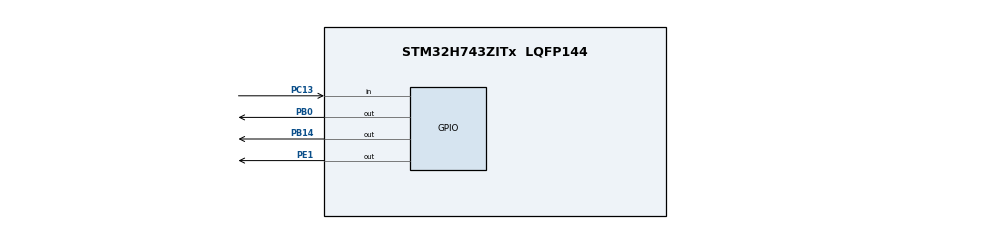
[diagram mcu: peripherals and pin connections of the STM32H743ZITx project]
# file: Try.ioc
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CORTEX_M7.default_mode_Activation=1
Mcu.Family=STM32H7
Mcu.Name=STM32H743ZITx
Mcu.Package=LQFP144
NUCLEO-H743ZI2.BUTTON=1
NUCLEO-H743ZI2.LD1=true
NUCLEO-H743ZI2.LD2=true
NUCLEO-H743ZI2.LD3=true
NUCLEO-H743ZI2.VCP=true
NVIC.EXTI15_10_IRQn=true\:0\:0\:false\:false\:true\:false\:true\:true
NVIC.PriorityGroup=NVIC_PRIORITYGROUP_4
PA13\ (JTMS/SWDIO).GPIO_Label=JTMS
PA13\ (JTMS/SWDIO).Signal=DEBUG_JTMS-SWDIO
PA14\ (JTCK/SWCLK).GPIO_Label=JTCK
PA14\ (JTCK/SWCLK).Signal=DEBUG_JTCK-SWCLK
PB0.Signal=GPIO_Output
PB14.Signal=GPIO_Output
PC13.Signal=GPIO_Input
PC14-OSC32_IN\ (OSC32_IN).Signal=RCC_OSC32_IN
PC15-OSC32_OUT\ (OSC32_OUT).Signal=RCC_OSC32_OUT
PD8.Signal=USART3_TX
PD9.Signal=USART3_RX
PE1.Signal=GPIO_Output
PH0-OSC_IN\ (PH0).Signal=RCC_OSC_IN
PH1-OSC_OUT\ (PH1).Signal=RCC_OSC_OUT
ProjectManager.HeapSize=0x200
ProjectManager.StackSize=0x400
ProjectManager.TargetToolchain=STM32CubeIDE
RCC.ADCFreq_Value=129000000
RCC.APB1Freq_Value=64000000
RCC.APB2Freq_Value=64000000
RCC.APB3Freq_Value=64000000
RCC.APB4Freq_Value=64000000
RCC.CortexFreq_Value=64000000
RCC.HCLKFreq_Value=64000000
RCC.SYSCLKFreq_VALUE=64000000
RCC.USBFreq_Value=129000000
VP_MEMORYMAP_VS_MEMORYMAP.Mode=CurAppReg
VP_NUCLEO-H743ZI2_VS_BSP_COMMON.Mode=COMMON
board=NUCLEO-H743ZI2

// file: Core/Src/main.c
/* USER CODE BEGIN Header */
/**
  ******************************************************************************
  * @file           : main.c
  * @brief          : Main program body
  ******************************************************************************
  * @attention
  *
  * Copyright (c) 2025 STMicroelectronics.
  * All rights reserved.
  *
  * This software is licensed under terms that can be found in the LICENSE file
  * in the root directory of this software component.
  * If no LICENSE file comes with this software, it is provided AS-IS.
  *
  ******************************************************************************
  */
/* USER CODE END Header */
#include "main.h"

/* USER CODE BEGIN PD */
#define var =500
/* USER CODE END PD */

/* USER CODE BEGIN PM */
int variable = 19;
//here i will intialize an usart3
/* USER CODE END PM */

COM_InitTypeDef BspCOMInit;

void SystemClock_Config(void);
static void MPU_Config(void);
static void MX_GPIO_Init(void);

int main(void)
{

  /* MPU Configuration--------------------------------------------------------*/
  MPU_Config();

  /* MCU Configuration--------------------------------------------------------*/

  /* Reset of all peripherals, Initializes the Flash interface and the Systick. */
  HAL_Init();

  /* Configure the system clock */
  SystemClock_Config();

  /* Initialize all configured peripherals */
  MX_GPIO_Init();

  /* Initialize leds */
  BSP_LED_Init(LED_GREEN);
  BSP_LED_Init(LED_YELLOW);
  BSP_LED_Init(LED_RED);

  /* Initialize USER push-button, will be used to trigger an interrupt each time it's pressed.*/
  BSP_PB_Init(BUTTON_USER, BUTTON_MODE_EXTI);

  /* Initialize COM1 port (115200, 8 bits (7-bit data + 1 stop bit), no parity */
  BspCOMInit.BaudRate   = 115200;
  BspCOMInit.WordLength = COM_WORDLENGTH_8B;
  BspCOMInit.StopBits   = COM_STOPBITS_1;
  BspCOMInit.Parity     = COM_PARITY_NONE;
  BspCOMInit.HwFlowCtl  = COM_HWCONTROL_NONE;
  if (BSP_COM_Init(COM1, &BspCOMInit) != BSP_ERROR_NONE)
  {
    Error_Handler();
  }

  /* Infinite loop */
  while (1)
  {

  }
}

void SystemClock_Config(void)
{
  RCC_OscInitTypeDef RCC_OscInitStruct = {0};
  RCC_ClkInitTypeDef RCC_ClkInitStruct = {0};

  /** Supply configuration update enable
  */
  HAL_PWREx_ConfigSupply(PWR_LDO_SUPPLY);

  /** Configure the main internal regulator output voltage
  */
  __HAL_PWR_VOLTAGESCALING_CONFIG(PWR_REGULATOR_VOLTAGE_SCALE3);

  while(!__HAL_PWR_GET_FLAG(PWR_FLAG_VOSRDY)) {}

  /** Initializes the RCC Oscillators according to the specified parameters
  * in the RCC_OscInitTypeDef structure.
  */
  RCC_OscInitStruct.OscillatorType = RCC_OSCILLATORTYPE_HSI;
  RCC_OscInitStruct.HSIState = RCC_HSI_DIV1;
  RCC_OscInitStruct.HSICalibrationValue = RCC_HSICALIBRATION_DEFAULT;
  RCC_OscInitStruct.PLL.PLLState = RCC_PLL_NONE;
  if (HAL_RCC_OscConfig(&RCC_OscInitStruct) != HAL_OK)
  {
    Error_Handler();
  }

  /** Initializes the CPU, AHB and APB buses clocks
  */
  RCC_ClkInitStruct.ClockType = RCC_CLOCKTYPE_HCLK|RCC_CLOCKTYPE_SYSCLK
                              |RCC_CLOCKTYPE_PCLK1|RCC_CLOCKTYPE_PCLK2
                              |RCC_CLOCKTYPE_D3PCLK1|RCC_CLOCKTYPE_D1PCLK1;
  RCC_ClkInitStruct.SYSCLKSource = RCC_SYSCLKSOURCE_HSI;
  RCC_ClkInitStruct.SYSCLKDivider = RCC_SYSCLK_DIV1;
  RCC_ClkInitStruct.AHBCLKDivider = RCC_HCLK_DIV1;
  RCC_ClkInitStruct.APB3CLKDivider = RCC_APB3_DIV1;
  RCC_ClkInitStruct.APB1CLKDivider = RCC_APB1_DIV1;
  RCC_ClkInitStruct.APB2CLKDivider = RCC_APB2_DIV1;
  RCC_ClkInitStruct.APB4CLKDivider = RCC_APB4_DIV1;

  if (HAL_RCC_ClockConfig(&RCC_ClkInitStruct, FLASH_LATENCY_1) != HAL_OK)
  {
    Error_Handler();
  }
}

static void MX_GPIO_Init(void)
{

  /* GPIO Ports Clock Enable */
  __HAL_RCC_GPIOC_CLK_ENABLE();
  __HAL_RCC_GPIOH_CLK_ENABLE();
  __HAL_RCC_GPIOA_CLK_ENABLE();

}

 /* MPU Configuration */

void MPU_Config(void)
{
  MPU_Region_InitTypeDef MPU_InitStruct = {0};

  /* Disables the MPU */
  HAL_MPU_Disable();

  /** Initializes and configures the Region and the memory to be protected
  */
  MPU_InitStruct.Enable = MPU_REGION_ENABLE;
  MPU_InitStruct.Number = MPU_REGION_NUMBER0;
  MPU_InitStruct.BaseAddress = 0x0;
  MPU_InitStruct.Size = MPU_REGION_SIZE_4GB;
  MPU_InitStruct.SubRegionDisable = 0x87;
  MPU_InitStruct.TypeExtField = MPU_TEX_LEVEL0;
  MPU_InitStruct.AccessPermission = MPU_REGION_NO_ACCESS;
  MPU_InitStruct.DisableExec = MPU_INSTRUCTION_ACCESS_DISABLE;
  MPU_InitStruct.IsShareable = MPU_ACCESS_SHAREABLE;
  MPU_InitStruct.IsCacheable = MPU_ACCESS_NOT_CACHEABLE;
  MPU_InitStruct.IsBufferable = MPU_ACCESS_NOT_BUFFERABLE;

  HAL_MPU_ConfigRegion(&MPU_InitStruct);
  /* Enables the MPU */
  HAL_MPU_Enable(MPU_PRIVILEGED_DEFAULT);

}

void Error_Handler(void)
{
  __disable_irq();
  while (1)
  {
  }
}
